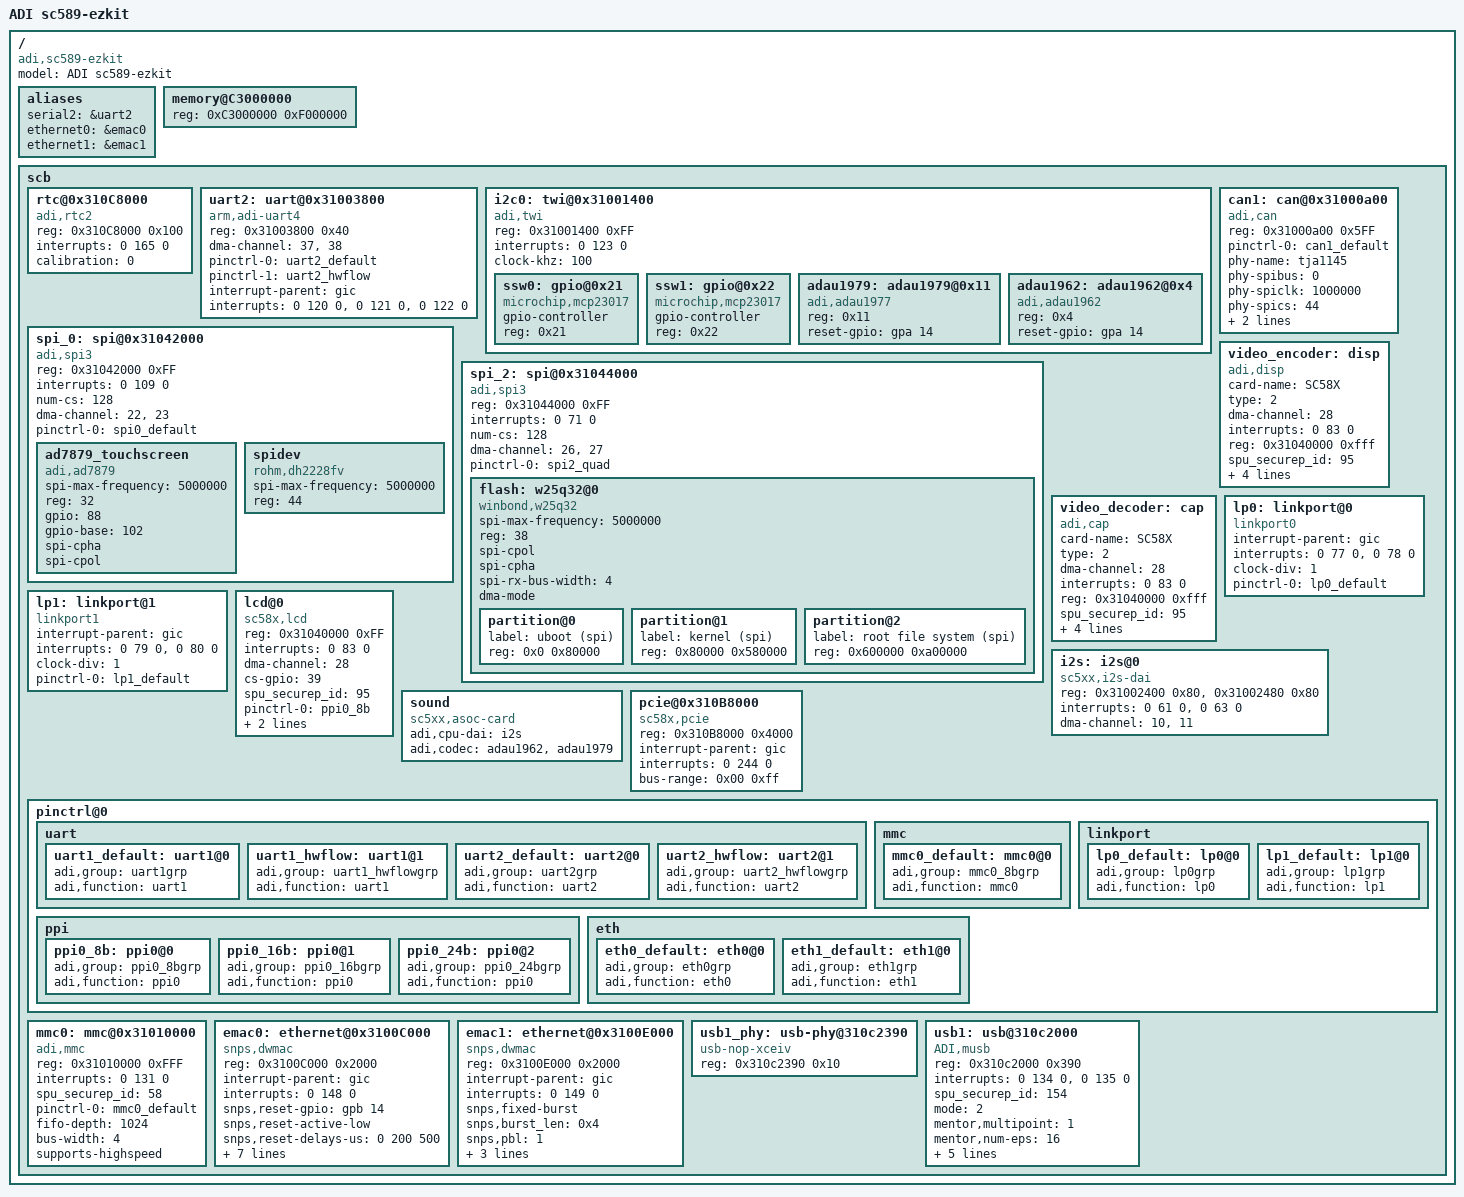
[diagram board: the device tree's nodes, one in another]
/*
 * Device tree for ADI sc589-ezkit board
 *
 * Copyright 2014 Analog Devices Inc.
 *
 * Licensed under the GPL-2 or later.
 *
 */

/dts-v1/;

/include/ "sc58x.dtsi"

/ {
	model = "ADI sc589-ezkit";
	compatible = "adi,sc589-ezkit", "adi,sc58x";

	aliases {
		/* serial1 = &uart1; */
		serial2 = &uart2;
		ethernet0 = &emac0;
		ethernet1 = &emac1;
	};

	memory@C3000000 {
		device_type = "memory";
		reg = <0xC3000000 0xF000000>;
	};

	scb {
		rtc@0x310C8000 {
			compatible = "adi,rtc2";
			reg = <0x310C8000 0x100>;
			interrupts = <0 165 0>;
			calibration = /bits/ 8 <0>;
		};

		/* uart1: uart@0x31003400 {
			compatible = "arm,adi-uart4";
			reg = <0x31003400 0x40>;
			dma-channel = <34>, <35>;
			pinctrl-names = "default", "hwflow";
			pinctrl-0 = <&uart1_default>;
			pinctrl-1 = <&uart1_hwflow>;
			interrupt-parent = <&gic>;
			interrupts = <0 117 0>,
			             <0 118 0>,
				     <0 119 0>;
		}; */

		uart2: uart@0x31003800 {
			compatible = "arm,adi-uart4";
			reg = <0x31003800 0x40>;
			dma-channel = <37>, <38>;
			pinctrl-names = "default", "hwflow";
			pinctrl-0 = <&uart2_default>;
			pinctrl-1 = <&uart2_hwflow>;
			interrupt-parent = <&gic>;
			interrupts = <0 120 0>,
			             <0 121 0>,
				     <0 122 0>;
		};

		i2c0: twi@0x31001400 {
			#address-cells = <1>;
			#size-cells = <0>;
			compatible = "adi,twi";
			reg = <0x31001400 0xFF>;
			interrupts = <0 123 0>;
			clock-khz = <100>;
			ssw0: gpio@0x21 {
				compatible = "microchip,mcp23017";
				gpio-controller;
				#gpio-cells = <2>;
				reg = <0x21>;
			};
			ssw1: gpio@0x22 {
				compatible = "microchip,mcp23017";
				gpio-controller;
				#gpio-cells = <2>;
				reg = <0x22>;
			};
			adau1979: adau1979@0x11 {
				compatible = "adi,adau1977";
				reg = <0x11>;
				reset-gpio = <&gpa 14 0>;
			};
			adau1962: adau1962@0x4 {
				compatible = "adi,adau1962";
				reg = <0x4>;
				reset-gpio = <&gpa 14 0>;
			};
		};

		spi_0: spi@0x31042000 {
			#address-cells = <1>;
			#size-cells = <0>;
			compatible = "adi,spi3";
			reg = <0x31042000 0xFF>;
			interrupts = <0 109 0>;
			num-cs = <128>;
			dma-channel = <22>, <23>;
			pinctrl-names = "default";
			pinctrl-0 = <&spi0_default>;

			ad7879_touchscreen {
				#address-cells = <1>;
				#size-cells = <1>;
				compatible = "adi,ad7879";
				spi-max-frequency = <5000000>;
				reg = <32>;
				gpio = <88>;
				gpio-base = <102>;
				spi-cpha;
				spi-cpol;
			};

			spidev {
				#address-cells = <1>;
				#size-cells = <1>;
				compatible = "rohm,dh2228fv";
				spi-max-frequency = <5000000>;
				reg = <44>;
			};
		};

		spi_2: spi@0x31044000 {
			#address-cells = <1>;
			#size-cells = <0>;
			compatible = "adi,spi3";
			reg = <0x31044000 0xFF>;
			interrupts = <0 71 0>;
			num-cs = <128>;
			dma-channel = <26>, <27>;
			pinctrl-names = "default";
			pinctrl-0 = <&spi2_quad>;

			flash: w25q32@0 {
				#address-cells = <1>;
				#size-cells = <1>;
				compatible = "winbond,w25q32";
				spi-max-frequency = <5000000>;
				reg = <38>;
				spi-cpol;
				spi-cpha;
				spi-rx-bus-width = <4>;
				dma-mode;

				partition@0 {
					label = "uboot (spi)";
					reg = <0x0 0x80000>;
				};
				partition@1 {
					label = "kernel (spi)";
					reg = <0x80000 0x580000>;
				};
				partition@2 {
					label = "root file system (spi)";
					reg = <0x600000 0xa00000>;
				};
			};
		};

		can1: can@0x31000a00 {
			compatible = "adi,can";
			reg = <0x31000a00 0x5FF>;
			pinctrl-names = "default";
			pinctrl-0 = <&can1_default>;
			phy-name = "tja1145";
			phy-spibus = /bits/ 16 <0>;
			phy-spiclk = <1000000>;
			phy-spics = /bits/ 16 <44>;	/* GPIO_PC12 */
			interrupt-parent = <&gic>;
			interrupts = <0 87 0>,
				     <0 88 0>,
				     <0 89 0>;
		};

		video_encoder: disp {
			compatible = "adi,disp";
			card-name = "SC58X";
			type = <2>;
			dma-channel = <28>;
			interrupts = <0 83 0>;
			reg = <0x31040000 0xfff>;
			spu_securep_id = <95>;
			i2c_bus_id = <0>;
			pinctrl-names = "8bit", "16bit", "24bit";
			pinctrl-0 = <&ppi0_8b>;
			pinctrl-1 = <&ppi0_16b>;
			pinctrl-2 = <&ppi0_24b>;
		};

		video_decoder: cap {
			compatible = "adi,cap";
			card-name = "SC58X";
			type = <2>;
			dma-channel = <28>;
			interrupts = <0 83 0>;
			reg = <0x31040000 0xfff>;
			spu_securep_id = <95>;
			i2c_bus_id = <0>;
			pinctrl-names = "8bit", "16bit", "24bit";
			pinctrl-0 = <&ppi0_8b>;
			pinctrl-1 = <&ppi0_16b>;
			pinctrl-2 = <&ppi0_24b>;
		};

		lp0: linkport@0 {
			compatible = "linkport0";
			interrupt-parent = <&gic>;
			interrupts = <0 77 0>,
				     <0 78 0>;
			clock-div = <1>;
			pinctrl-names = "default";
			pinctrl-0 = <&lp0_default>;
		};

		lp1: linkport@1 {
			compatible = "linkport1";
			interrupt-parent = <&gic>;
			interrupts = <0 79 0>,
				     <0 80 0>;
			clock-div = <1>;
			pinctrl-names = "default";
			pinctrl-0 = <&lp1_default>;
		};

		lcd@0 {
			compatible = "sc58x,lcd";
			reg = <0x31040000 0xFF>;
			interrupts = <0 83 0>;
			dma-channel = <28>;
			cs-gpio = <39>;
			spu_securep_id = <95>;
			pinctrl-names = "default", "ppi_16b", "ppi_24b";
			pinctrl-0 = <&ppi0_8b>;
			pinctrl-1 = <&ppi0_16b>;
			pinctrl-2 = <&ppi0_24b>;
		};

		i2s: i2s@0 {
			compatible = "sc5xx,i2s-dai";
			reg = <0x31002400 0x80>, <0x31002480 0x80>;
			interrupts = <0 61 0>, <0 63 0>;
			dma-channel = <10>, <11>;
		};

		sound {
			compatible = "sc5xx,asoc-card";
			adi,cpu-dai = <&i2s>;
			adi,codec = <&adau1962>, <&adau1979>;
		};

		pcie@0x310B8000 {
			compatible = "sc58x,pcie";
			reg = <0x310B8000 0x4000>;
			#address-cells = <3>;
			#size-cells = <2>;
			device_type = "pci";

			interrupt-parent = <&gic>;
			interrupts = <0 244 0>;	/* status interrupt */
			#interrupt-cells = <1>;

			bus-range = <0x00 0xff>;
			ranges = <0x00000000 0 0x5f000000 0x5f000000 0 0x01000000   /* configuration space */
				  0x82000000 0 0x5e000000 0x5e000000 0 0x01000000   /* non-prefetchable memory */
				  0xc2000000 0 0x50000000 0x50000000 0 0x0e000000>; /* prefetchable memory */
		};

		pinctrl@0 {
			uart {
				uart1_default: uart1@0 {
					adi,group = "uart1grp";
					adi,function = "uart1";
				};
				uart1_hwflow: uart1@1 {
					adi,group = "uart1_hwflowgrp";
					adi,function = "uart1";
				};
				uart2_default: uart2@0 {
					adi,group = "uart2grp";
					adi,function = "uart2";
				};
				uart2_hwflow: uart2@1 {
					adi,group = "uart2_hwflowgrp";
					adi,function = "uart2";
				};
			};

			mmc {
				mmc0_default: mmc0@0 {
					adi,group = "mmc0_8bgrp";
					adi,function = "mmc0";
				};
			};

			ppi {
				ppi0_8b: ppi0@0 {
					adi,group = "ppi0_8bgrp";
					adi,function = "ppi0";
				};
				ppi0_16b: ppi0@1 {
					adi,group = "ppi0_16bgrp";
					adi,function = "ppi0";
				};
				ppi0_24b: ppi0@2 {
					adi,group = "ppi0_24bgrp";
					adi,function = "ppi0";
				};
			};

			eth {
				eth0_default: eth0@0 {
					adi,group = "eth0grp";
					adi,function = "eth0";
				};
				eth1_default: eth1@0 {
					adi,group = "eth1grp";
					adi,function = "eth1";
				};
			};

			linkport {
				lp0_default: lp0@0 {
					adi,group = "lp0grp";
					adi,function = "lp0";
				};
				lp1_default: lp1@0 {
					adi,group = "lp1grp";
					adi,function = "lp1";
				};
			};
		};

		mmc0: mmc@0x31010000 {
			compatible = "adi,mmc";
			reg = <0x31010000 0xFFF>;
			interrupts = <0 131 0>;
			spu_securep_id = <58>;
			pinctrl-names = "default";
			pinctrl-0 = <&mmc0_default>;
			#address-cells = <1>;
			#size-cells = <0>;
			fifo-depth = <1024>;
			bus-width = <4>;
			supports-highspeed;
		};

		emac0: ethernet@0x3100C000 {
			compatible = "snps,dwmac", "snps,dwmac-3.710";
			reg = <0x3100C000 0x2000>;
			interrupt-parent = <&gic>;
			interrupts = <0 148 0>;
			interrupt-names = "macirq";
			snps,reset-gpio = <&gpb 14 0>;
			snps,reset-active-low;
			snps,reset-delays-us = <0 200 500>;
			snps,fixed-burst;
			snps,burst_len = <0x8>;	/* BLEN16 */
			snps,pbl = <2>;
			snps,force_sf_dma_mode;
			snps,perfect-filter-entries = <32>;
			phy-mode = "rgmii";
			clock-names = "stmmaceth";
			pinctrl-names = "default";
			pinctrl-0 = <&eth0_default>;
		};

		emac1: ethernet@0x3100E000 {
			compatible = "snps,dwmac", "snps,dwmac-3.710";
			reg = <0x3100E000 0x2000>;
			interrupt-parent = <&gic>;
			interrupts = <0 149 0>;
			interrupt-names = "macirq";
			snps,fixed-burst;
			snps,burst_len = <0x4>;	/* BLEN8 */
			snps,pbl = <1>;
			snps,force_thresh_dma_mode;
			phy-mode = "rmii";
			clock-names = "stmmaceth";
			pinctrl-names = "default";
			pinctrl-0 = <&eth1_default>;
		};

		usb1_phy: usb-phy@310c2390 {
			compatible = "usb-nop-xceiv";
			reg = <0x310c2390 0x10>;
			reg-names = "phy";
		};

		usb1: usb@310c2000 {
			compatible = "ADI,musb";
			reg = <0x310c2000 0x390>;
			reg-names = "mc";
			interrupts = <0 134 0>,
						 <0 135 0>;
			interrupt-names = "mc", "dma";
			spu_securep_id = <154>;

			mode = <2>; /* Device */
			mentor,multipoint = <1>;
			mentor,num-eps = <16>;
			mentor,ram-bits = <12>;
			mentor,dma-channels = <8>;
			memtor,dyn-fifo = <0>;
			mentor,power = <500>;
			phys = <&usb1_phy>;
		};
	};
};
